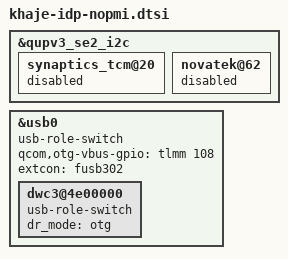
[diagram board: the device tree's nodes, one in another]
#include "khaje-idp.dtsi"

&qupv3_se2_i2c {
	synaptics_tcm@20 {
		status = "disabled";
	};

	novatek@62 {
		status = "disabled";
	};
};

&usb0 {
	usb-role-switch;
	///delete-property/ extcon;
	/* nopmi: use GPIO boost for OTG VBUS (same as bengal-usb.dtsi) */
	qcom,otg-vbus-gpio = <&tlmm 108 0>;
	extcon = <&fusb302>;
	dwc3@4e00000 {
		usb-role-switch;
		dr_mode = "otg";
	};
};
